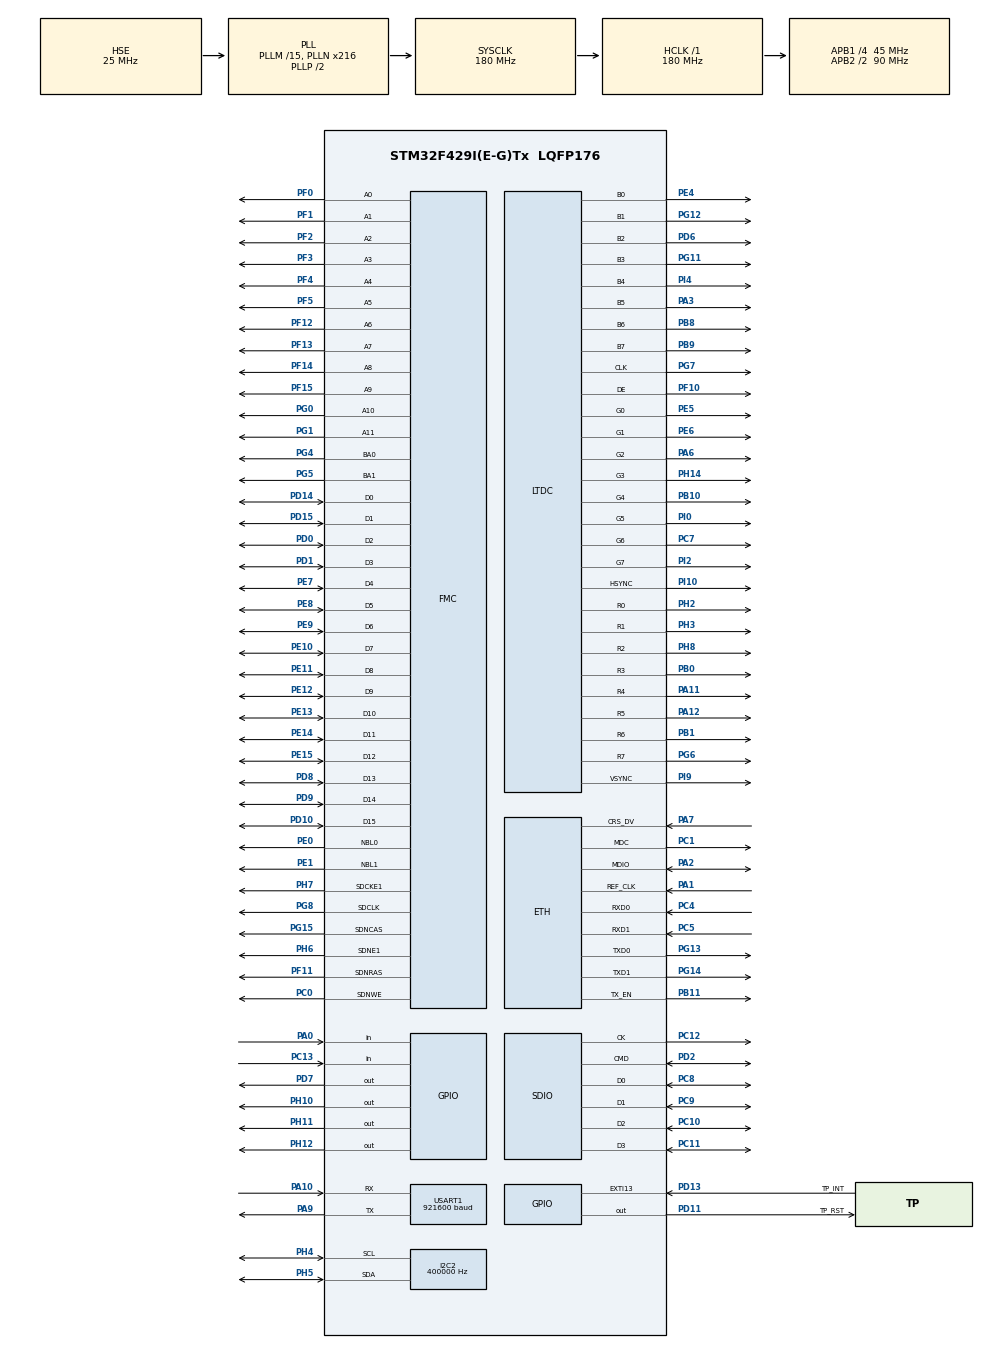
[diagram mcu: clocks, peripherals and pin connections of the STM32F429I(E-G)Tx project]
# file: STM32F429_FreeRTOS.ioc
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ADC1.Channel-0\#ChannelRegularConversion=ADC_CHANNEL_TEMPSENSOR
ADC1.NbrOfConversionFlag=1
ADC1.Rank-0\#ChannelRegularConversion=1
ADC1.SamplingTime-0\#ChannelRegularConversion=ADC_SAMPLETIME_3CYCLES
ADC1.master=1
DMA2D.ColorMode=DMA2D_OUTPUT_RGB888
DMA2D.Mode=DMA2D_M2M
Dma.Request0=SDIO_RX
Dma.Request1=SDIO_TX
Dma.SDIO_RX.0.Direction=DMA_PERIPH_TO_MEMORY
Dma.SDIO_RX.0.FIFOMode=DMA_FIFOMODE_ENABLE
Dma.SDIO_RX.0.FIFOThreshold=DMA_FIFO_THRESHOLD_FULL
Dma.SDIO_RX.0.Instance=DMA2_Stream3
Dma.SDIO_RX.0.MemBurst=DMA_MBURST_INC4
Dma.SDIO_RX.0.MemDataAlignment=DMA_MDATAALIGN_WORD
Dma.SDIO_RX.0.MemInc=DMA_MINC_ENABLE
Dma.SDIO_RX.0.Mode=DMA_PFCTRL
Dma.SDIO_RX.0.PeriphBurst=DMA_PBURST_INC4
Dma.SDIO_RX.0.PeriphDataAlignment=DMA_PDATAALIGN_WORD
Dma.SDIO_RX.0.PeriphInc=DMA_PINC_DISABLE
Dma.SDIO_RX.0.Priority=DMA_PRIORITY_LOW
Dma.SDIO_TX.1.Direction=DMA_MEMORY_TO_PERIPH
Dma.SDIO_TX.1.FIFOMode=DMA_FIFOMODE_ENABLE
Dma.SDIO_TX.1.FIFOThreshold=DMA_FIFO_THRESHOLD_FULL
Dma.SDIO_TX.1.Instance=DMA2_Stream6
Dma.SDIO_TX.1.MemBurst=DMA_MBURST_INC4
Dma.SDIO_TX.1.MemDataAlignment=DMA_MDATAALIGN_WORD
Dma.SDIO_TX.1.MemInc=DMA_MINC_ENABLE
Dma.SDIO_TX.1.Mode=DMA_PFCTRL
Dma.SDIO_TX.1.PeriphBurst=DMA_PBURST_INC4
Dma.SDIO_TX.1.PeriphDataAlignment=DMA_PDATAALIGN_WORD
Dma.SDIO_TX.1.PeriphInc=DMA_PINC_DISABLE
Dma.SDIO_TX.1.Priority=DMA_PRIORITY_LOW
ETH.MediaInterface=ETH_MEDIA_INTERFACE_RMII
ETH.PHY_DUPLEX_STATUS=0x0010
ETH.PHY_Name_RMII=userPHY
ETH.PHY_SPEED_STATUS=0x0004
ETH.PHY_SR=0x1F
ETH.PHY_User_Name=LAN8720A_PHY_ADDRESS
ETH.PhyAddress=0
FATFS._CODE_PAGE=936
FATFS._USE_LFN=2
FMC.CASLatency1=FMC_SDRAM_CAS_LATENCY_3
FMC.ExitSelfRefreshDelay1=7
FMC.LoadToActiveDelay1=2
FMC.RCDDelay1=2
FMC.RPDelay1=2
FMC.RPDelay2=2
FMC.ReadPipeDelay1=FMC_SDRAM_RPIPE_DELAY_1
FMC.ReadPipeDelay2=FMC_SDRAM_RPIPE_DELAY_1
FMC.RowCycleDelay1=7
FMC.RowCycleDelay2=7
FMC.SDClockPeriod1=FMC_SDRAM_CLOCK_PERIOD_2
FMC.SDClockPeriod2=FMC_SDRAM_CLOCK_PERIOD_2
FMC.SelfRefreshTime1=4
FMC.WriteRecoveryTime1=3
FREERTOS.Tasks01=defaultTask,24,128,StartDefaultTask,Default,(void *)semaphore,Dynamic,NULL,NULL
FREERTOS.configENABLE_FPU=1
FREERTOS.configGENERATE_RUN_TIME_STATS=1
FREERTOS.configLIBRARY_MAX_SYSCALL_INTERRUPT_PRIORITY=5
FREERTOS.configMINIMAL_STACK_SIZE=128
FREERTOS.configTOTAL_HEAP_SIZE=51200
FREERTOS.configUSE_STATS_FORMATTING_FUNCTIONS=1
I2C2.ClockSpeed=400000
I2C2.DutyCycle=I2C_DUTYCYCLE_2
I2C2.I2C_Mode=I2C_Fast
I2C2.OwnAddress=0x10
LTDC.ActiveH=600
LTDC.ActiveW=1024
LTDC.Alpha_L0=255
LTDC.BlendingFactor1_L0=LTDC_BLENDING_FACTOR1_CA
LTDC.BlendingFactor2_L0=LTDC_BLENDING_FACTOR2_CA
LTDC.FBStartAdress_L0=0xD0000000
LTDC.HBP=140
LTDC.HFP=160
LTDC.HSync=20
LTDC.ImageHeight_L0=600
LTDC.ImageWidth_L0=1024
LTDC.Layers=0
LTDC.PixelFormat_L0=LTDC_PIXEL_FORMAT_RGB888
LTDC.VBP=20
LTDC.VFP=12
LTDC.VSync=3
LTDC.WindowX1_L0=1024
LTDC.WindowY1_L0=600
LWIP.GATEWAY_ADDRESS=192.168.000.001
LWIP.IP_ADDRESS=192.168.000.123
LWIP.LWIP_DHCP=0
LWIP.LWIP_NETIF_STATUS_CALLBACK=1
LWIP.LWIP_SNTP=0
LWIP.LWIP_TCPIP_CORE_LOCKING=0
LWIP.LWIP_TCPIP_CORE_LOCKING_INPUT=0
LWIP.MEMP_NUM_SYS_TIMEOUT=7
LWIP.MEM_SIZE=(16*1024)
LWIP.NETMASK_ADDRESS=255.255.255.000
LWIP.TCPIP_THREAD_STACKSIZE=512 * 4
LWIP.Version=v2.1.2_Cube
Mcu.Family=STM32F4
Mcu.Name=STM32F429I(E-G)Tx
Mcu.Package=LQFP176
NVIC.DMA2_Stream3_IRQn=true\:7\:0\:true\:false\:true\:true\:false\:true
NVIC.DMA2_Stream6_IRQn=true\:7\:0\:true\:false\:true\:true\:false\:true
NVIC.ETH_IRQn=true\:5\:0\:false\:false\:true\:true\:false\:true
NVIC.EXTI15_10_IRQn=true\:5\:0\:false\:false\:true\:true\:true\:true
NVIC.PriorityGroup=NVIC_PRIORITYGROUP_4
NVIC.SDIO_IRQn=true\:6\:0\:true\:false\:true\:true\:true\:true
NVIC.TIM6_DAC_IRQn=true\:5\:0\:false\:false\:true\:true\:true\:true
NVIC.TIM7_IRQn=true\:15\:0\:false\:false\:true\:false\:false\:true
NVIC.TimeBase=TIM7_IRQn
NVIC.TimeBaseIP=TIM7
PA0/WKUP.Signal=GPIO_Input
PA1.Mode=RMII
PA1.Signal=ETH_REF_CLK
PA10.Mode=Asynchronous
PA10.Signal=USART1_RX
PA11.GPIO_Speed=GPIO_SPEED_FREQ_VERY_HIGH
PA11.Mode=RGB888
PA11.Signal=LTDC_R4
PA12.GPIO_Speed=GPIO_SPEED_FREQ_VERY_HIGH
PA12.Mode=RGB888
PA12.Signal=LTDC_R5
PA13.Mode=Serial_Wire
PA13.Signal=SYS_JTMS-SWDIO
PA14.Mode=Serial_Wire
PA14.Signal=SYS_JTCK-SWCLK
PA2.Mode=RMII
PA2.Signal=ETH_MDIO
PA3.GPIO_Speed=GPIO_SPEED_FREQ_VERY_HIGH
PA3.Mode=RGB888
PA3.Signal=LTDC_B5
PA6.GPIO_Speed=GPIO_SPEED_FREQ_VERY_HIGH
PA6.Mode=RGB888
PA6.Signal=LTDC_G2
PA7.Mode=RMII
PA7.Signal=ETH_CRS_DV
PA9.Mode=Asynchronous
PA9.Signal=USART1_TX
PB0.GPIO_Speed=GPIO_SPEED_FREQ_VERY_HIGH
PB0.Mode=RGB888
PB0.Signal=LTDC_R3
PB1.GPIO_Speed=GPIO_SPEED_FREQ_VERY_HIGH
PB1.Mode=RGB888
PB1.Signal=LTDC_R6
PB10.GPIO_Speed=GPIO_SPEED_FREQ_VERY_HIGH
PB10.Mode=RGB888
PB10.Signal=LTDC_G4
PB11.Mode=RMII
PB11.Signal=ETH_TX_EN
PB8.GPIO_Speed=GPIO_SPEED_FREQ_VERY_HIGH
PB8.Mode=RGB888
PB8.Signal=LTDC_B6
PB9.GPIO_Speed=GPIO_SPEED_FREQ_VERY_HIGH
PB9.Mode=RGB888
PB9.Signal=LTDC_B7
PC0.Signal=FMC_SDNWE
PC1.Mode=RMII
PC1.Signal=ETH_MDC
PC10.GPIO_PuPd=GPIO_NOPULL
PC10.Mode=SD_4_bits_Wide_bus
PC10.Signal=SDIO_D2
PC11.GPIO_PuPd=GPIO_NOPULL
PC11.Mode=SD_4_bits_Wide_bus
PC11.Signal=SDIO_D3
PC12.GPIO_PuPd=GPIO_NOPULL
PC12.Mode=SD_4_bits_Wide_bus
PC12.Signal=SDIO_CK
PC13.Signal=GPIO_Input
PC14/OSC32_IN.Mode=LSE-External-Oscillator
PC14/OSC32_IN.Signal=RCC_OSC32_IN
PC15/OSC32_OUT.Mode=LSE-External-Oscillator
PC15/OSC32_OUT.Signal=RCC_OSC32_OUT
PC4.Mode=RMII
PC4.Signal=ETH_RXD0
PC5.Mode=RMII
PC5.Signal=ETH_RXD1
PC7.GPIO_Speed=GPIO_SPEED_FREQ_VERY_HIGH
PC7.Mode=RGB888
PC7.Signal=LTDC_G6
PC8.GPIO_PuPd=GPIO_NOPULL
PC8.Mode=SD_4_bits_Wide_bus
PC8.Signal=SDIO_D0
PC9.GPIO_PuPd=GPIO_NOPULL
PC9.Mode=SD_4_bits_Wide_bus
PC9.Signal=SDIO_D1
PD0.Signal=FMC_D2_DA2
PD1.Signal=FMC_D3_DA3
PD10.Signal=FMC_D15_DA15
PD11.GPIO_Label=TP_RST
PD11.Signal=GPIO_Output
PD13.GPIO_Label=TP_INT
PD13.GPIO_ModeDefaultEXTI=GPIO_MODE_IT_RISING
PD13.Signal=GPXTI13
PD14.Signal=FMC_D0_DA0
PD15.Signal=FMC_D1_DA1
PD2.GPIO_PuPd=GPIO_NOPULL
PD2.Mode=SD_4_bits_Wide_bus
PD2.Signal=SDIO_CMD
PD6.GPIO_Speed=GPIO_SPEED_FREQ_VERY_HIGH
PD6.Mode=RGB888
PD6.Signal=LTDC_B2
PD7.PinState=GPIO_PIN_SET
PD7.Signal=GPIO_Output
PD8.Signal=FMC_D13_DA13
PD9.Signal=FMC_D14_DA14
PE0.Signal=FMC_NBL0
PE1.Signal=FMC_NBL1
PE10.Signal=FMC_D7_DA7
PE11.Signal=FMC_D8_DA8
PE12.Signal=FMC_D9_DA9
PE13.Signal=FMC_D10_DA10
PE14.Signal=FMC_D11_DA11
PE15.Signal=FMC_D12_DA12
PE4.GPIO_Speed=GPIO_SPEED_FREQ_VERY_HIGH
PE4.Mode=RGB888
PE4.Signal=LTDC_B0
PE5.GPIO_Speed=GPIO_SPEED_FREQ_VERY_HIGH
PE5.Mode=RGB888
PE5.Signal=LTDC_G0
PE6.GPIO_Speed=GPIO_SPEED_FREQ_VERY_HIGH
PE6.Mode=RGB888
PE6.Signal=LTDC_G1
PE7.Signal=FMC_D4_DA4
PE8.Signal=FMC_D5_DA5
PE9.Signal=FMC_D6_DA6
PF0.Signal=FMC_A0
PF1.Signal=FMC_A1
PF10.GPIO_Speed=GPIO_SPEED_FREQ_VERY_HIGH
PF10.Mode=RGB888
PF10.Signal=LTDC_DE
PF11.Signal=FMC_SDNRAS
PF12.Signal=FMC_A6
PF13.Signal=FMC_A7
PF14.Signal=FMC_A8
PF15.Signal=FMC_A9
PF2.Signal=FMC_A2
PF3.Signal=FMC_A3
PF4.Signal=FMC_A4
PF5.Signal=FMC_A5
PG0.Signal=FMC_A10
PG1.Signal=FMC_A11
PG11.GPIO_Speed=GPIO_SPEED_FREQ_VERY_HIGH
PG11.Mode=RGB888
PG11.Signal=LTDC_B3
PG12.GPIO_Speed=GPIO_SPEED_FREQ_VERY_HIGH
PG12.Mode=RGB888
PG12.Signal=LTDC_B1
PG13.Mode=RMII
PG13.Signal=ETH_TXD0
PG14.Mode=RMII
PG14.Signal=ETH_TXD1
PG15.Signal=FMC_SDNCAS
PG4.Signal=FMC_A14_BA0
PG5.Signal=FMC_A15_BA1
PG6.GPIO_Speed=GPIO_SPEED_FREQ_VERY_HIGH
PG6.Mode=RGB888
PG6.Signal=LTDC_R7
PG7.GPIO_Speed=GPIO_SPEED_FREQ_VERY_HIGH
PG7.Mode=RGB888
PG7.Signal=LTDC_CLK
PG8.Signal=FMC_SDCLK
PH0/OSC_IN.Mode=HSE-External-Oscillator
PH0/OSC_IN.Signal=RCC_OSC_IN
PH1/OSC_OUT.Mode=HSE-External-Oscillator
PH1/OSC_OUT.Signal=RCC_OSC_OUT
PH10.PinState=GPIO_PIN_SET
PH10.Signal=GPIO_Output
PH11.PinState=GPIO_PIN_SET
PH11.Signal=GPIO_Output
PH12.PinState=GPIO_PIN_SET
PH12.Signal=GPIO_Output
PH14.GPIO_Speed=GPIO_SPEED_FREQ_VERY_HIGH
PH14.Mode=RGB888
PH14.Signal=LTDC_G3
PH2.GPIO_Speed=GPIO_SPEED_FREQ_VERY_HIGH
PH2.Mode=RGB888
PH2.Signal=LTDC_R0
PH3.GPIO_Speed=GPIO_SPEED_FREQ_VERY_HIGH
PH3.Mode=RGB888
PH3.Signal=LTDC_R1
PH4.Mode=I2C
PH4.Signal=I2C2_SCL
PH5.Mode=I2C
PH5.Signal=I2C2_SDA
PH6.Mode=SdramChipSelect2_1
PH6.Signal=FMC_SDNE1
PH7.Mode=SdramChipSelect2_1
PH7.Signal=FMC_SDCKE1
PH8.GPIO_Speed=GPIO_SPEED_FREQ_VERY_HIGH
PH8.Mode=RGB888
PH8.Signal=LTDC_R2
PI0.GPIO_Speed=GPIO_SPEED_FREQ_VERY_HIGH
PI0.Mode=RGB888
PI0.Signal=LTDC_G5
PI10.GPIO_Speed=GPIO_SPEED_FREQ_VERY_HIGH
PI10.Mode=RGB888
PI10.Signal=LTDC_HSYNC
PI2.GPIO_Speed=GPIO_SPEED_FREQ_VERY_HIGH
PI2.Mode=RGB888
PI2.Signal=LTDC_G7
PI4.GPIO_Speed=GPIO_SPEED_FREQ_VERY_HIGH
PI4.Mode=RGB888
PI4.Signal=LTDC_B4
PI9.GPIO_Speed=GPIO_SPEED_FREQ_VERY_HIGH
PI9.Mode=RGB888
PI9.Signal=LTDC_VSYNC
ProjectManager.HeapSize=0x1000
ProjectManager.StackSize=0x1000
ProjectManager.TargetToolchain=STM32CubeIDE
RCC.48MHZClocksFreq_Value=45000000
RCC.AHBFreq_Value=180000000
RCC.APB1CLKDivider=RCC_HCLK_DIV4
RCC.APB1Freq_Value=45000000
RCC.APB1TimFreq_Value=90000000
RCC.APB2CLKDivider=RCC_HCLK_DIV2
RCC.APB2Freq_Value=90000000
RCC.APB2TimFreq_Value=180000000
RCC.CortexFreq_Value=180000000
RCC.HCLKFreq_Value=180000000
RCC.HSE_VALUE=25000000
RCC.HSI_VALUE=16000000
RCC.PLLM=15
RCC.PLLN=216
RCC.PLLQ=8
RCC.PLLSAIN=60
RCC.PLLSourceVirtual=RCC_PLLSOURCE_HSE
RCC.SYSCLKFreq_VALUE=180000000
RCC.SYSCLKSource=RCC_SYSCLKSOURCE_PLLCLK
RCC.VCOOutputFreq_Value=360000000
SDIO.ClockDiv=0
SDIO.HardwareFlowControl=SDIO_HARDWARE_FLOW_CONTROL_DISABLE
SH.FMC_A0.0=FMC_A0,12b-sda1
SH.FMC_A1.0=FMC_A1,12b-sda1
SH.FMC_A10.0=FMC_A10,12b-sda1
SH.FMC_A11.0=FMC_A11,12b-sda1
SH.FMC_A14_BA0.0=FMC_BA0,FourSdramBanks1
SH.FMC_A15_BA1.0=FMC_BA1,FourSdramBanks1
SH.FMC_A2.0=FMC_A2,12b-sda1
SH.FMC_A3.0=FMC_A3,12b-sda1
SH.FMC_A4.0=FMC_A4,12b-sda1
SH.FMC_A5.0=FMC_A5,12b-sda1
SH.FMC_A6.0=FMC_A6,12b-sda1
SH.FMC_A7.0=FMC_A7,12b-sda1
SH.FMC_A8.0=FMC_A8,12b-sda1
SH.FMC_A9.0=FMC_A9,12b-sda1
SH.FMC_D0_DA0.0=FMC_D0,sd-16b-d1
SH.FMC_D10_DA10.0=FMC_D10,sd-16b-d1
SH.FMC_D11_DA11.0=FMC_D11,sd-16b-d1
SH.FMC_D12_DA12.0=FMC_D12,sd-16b-d1
SH.FMC_D13_DA13.0=FMC_D13,sd-16b-d1
SH.FMC_D14_DA14.0=FMC_D14,sd-16b-d1
SH.FMC_D15_DA15.0=FMC_D15,sd-16b-d1
SH.FMC_D1_DA1.0=FMC_D1,sd-16b-d1
SH.FMC_D2_DA2.0=FMC_D2,sd-16b-d1
SH.FMC_D3_DA3.0=FMC_D3,sd-16b-d1
SH.FMC_D4_DA4.0=FMC_D4,sd-16b-d1
SH.FMC_D5_DA5.0=FMC_D5,sd-16b-d1
SH.FMC_D6_DA6.0=FMC_D6,sd-16b-d1
SH.FMC_D7_DA7.0=FMC_D7,sd-16b-d1
SH.FMC_D8_DA8.0=FMC_D8,sd-16b-d1
SH.FMC_D9_DA9.0=FMC_D9,sd-16b-d1
SH.FMC_NBL0.0=FMC_NBL0,Sd2ByteEnable1
SH.FMC_NBL1.0=FMC_NBL1,Sd2ByteEnable1
SH.FMC_SDCLK.0=FMC_SDCLK,12b-sda1
SH.FMC_SDNCAS.0=FMC_SDNCAS,12b-sda1
SH.FMC_SDNRAS.0=FMC_SDNRAS,12b-sda1
SH.FMC_SDNWE.0=FMC_SDNWE,12b-sda1
TIM6.AutoReloadPreload=TIM_AUTORELOAD_PRELOAD_ENABLE
TIM6.Period=899
TIM6.Prescaler=9
TIM6.TIM_MasterOutputTrigger=TIM_TRGO_UPDATE
USART1.BaudRate=921600
USART1.VirtualMode=VM_ASYNC
VP_ADC1_TempSens_Input.Mode=IN-TempSens
VP_CRC_VS_CRC.Mode=CRC_Activate
VP_DMA2D_VS_DMA2D.Mode=DMA2D_Activate
VP_FATFS_VS_SDIO.Mode=SDIO
VP_FREERTOS_VS_CMSIS_V2.Mode=CMSIS_V2
VP_LWIP_VS_Enabled.Mode=Enabled
VP_RNG_VS_RNG.Mode=RNG_Activate
VP_SYS_VS_tim7.Mode=TIM7
VP_TIM6_VS_ClockSourceINT.Mode=Enable_Timer
board=custom

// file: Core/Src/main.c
/* USER CODE BEGIN Header */
/**
  ******************************************************************************
  * @file           : main.c
  * @brief          : Main program body
  ******************************************************************************
  * @attention
  *
  * Copyright (c) 2023 STMicroelectronics.
  * All rights reserved.
  *
  * This software is licensed under terms that can be found in the LICENSE file
  * in the root directory of this software component.
  * If no LICENSE file comes with this software, it is provided AS-IS.
  *
  ******************************************************************************
  */
#include <stdio.h>
#include "sdio.h"
/* USER CODE END Header */
#include "main.h"
#include "cmsis_os.h"
#include "adc.h"
#include "crc.h"
#include "dma.h"
#include "dma2d.h"
#include "fatfs.h"
#include "i2c.h"
#include "ltdc.h"
#include "lwip.h"
#include "rng.h"
#include "sdio.h"
#include "tim.h"
#include "usart.h"
#include "gpio.h"
#include "fmc.h"

void SystemClock_Config(void);
void MX_FREERTOS_Init(void);

int main(void)
{

  /* MCU Configuration--------------------------------------------------------*/

  /* Reset of all peripherals, Initializes the Flash interface and the Systick. */
  HAL_Init();

  /* Configure the system clock */
  SystemClock_Config();

  /* Initialize all configured peripherals */
  MX_GPIO_Init();
  MX_SDIO_SD_Init();
  MX_USART1_UART_Init();
  MX_DMA_Init();
  MX_FATFS_Init();
  MX_CRC_Init();
  MX_DMA2D_Init();
  MX_FMC_Init();
  MX_LTDC_Init();
  MX_RNG_Init();
  MX_ADC1_Init();
  MX_TIM6_Init();
  MX_I2C2_Init();

  /* Init scheduler */
  osKernelInitialize();  /* Call init function for freertos objects (in freertos.c) */
  MX_FREERTOS_Init();
  /* Start scheduler */
  osKernelStart();

  /* We should never get here as control is now taken by the scheduler */
  /* Infinite loop */
  while (1)
  {

  }
}

void SystemClock_Config(void)
{
  RCC_OscInitTypeDef RCC_OscInitStruct = {0};
  RCC_ClkInitTypeDef RCC_ClkInitStruct = {0};

  /** Configure the main internal regulator output voltage
  */
  __HAL_RCC_PWR_CLK_ENABLE();
  __HAL_PWR_VOLTAGESCALING_CONFIG(PWR_REGULATOR_VOLTAGE_SCALE1);
  /** Initializes the RCC Oscillators according to the specified parameters
  * in the RCC_OscInitTypeDef structure.
  */
  RCC_OscInitStruct.OscillatorType = RCC_OSCILLATORTYPE_HSE;
  RCC_OscInitStruct.HSEState = RCC_HSE_ON;
  RCC_OscInitStruct.PLL.PLLState = RCC_PLL_ON;
  RCC_OscInitStruct.PLL.PLLSource = RCC_PLLSOURCE_HSE;
  RCC_OscInitStruct.PLL.PLLM = 15;
  RCC_OscInitStruct.PLL.PLLN = 216;
  RCC_OscInitStruct.PLL.PLLP = RCC_PLLP_DIV2;
  RCC_OscInitStruct.PLL.PLLQ = 8;
  if (HAL_RCC_OscConfig(&RCC_OscInitStruct) != HAL_OK)
  {
    Error_Handler();
  }
  /** Activate the Over-Drive mode
  */
  if (HAL_PWREx_EnableOverDrive() != HAL_OK)
  {
    Error_Handler();
  }
  /** Initializes the CPU, AHB and APB buses clocks
  */
  RCC_ClkInitStruct.ClockType = RCC_CLOCKTYPE_HCLK|RCC_CLOCKTYPE_SYSCLK
                              |RCC_CLOCKTYPE_PCLK1|RCC_CLOCKTYPE_PCLK2;
  RCC_ClkInitStruct.SYSCLKSource = RCC_SYSCLKSOURCE_PLLCLK;
  RCC_ClkInitStruct.AHBCLKDivider = RCC_SYSCLK_DIV1;
  RCC_ClkInitStruct.APB1CLKDivider = RCC_HCLK_DIV4;
  RCC_ClkInitStruct.APB2CLKDivider = RCC_HCLK_DIV2;

  if (HAL_RCC_ClockConfig(&RCC_ClkInitStruct, FLASH_LATENCY_5) != HAL_OK)
  {
    Error_Handler();
  }
}

void HAL_TIM_PeriodElapsedCallback(TIM_HandleTypeDef *htim)
{
  if (htim->Instance == TIM7) {
    HAL_IncTick();
  }
  /* USER CODE BEGIN Callback 1 */
  if(htim->Instance == TIM6){
  		timer_cnt++;
  	}
  /* USER CODE END Callback 1 */
}

void Error_Handler(void)
{
  __disable_irq();
  while (1)
  {
  }
}

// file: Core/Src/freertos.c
/* USER CODE BEGIN Header */
/**
  ******************************************************************************
  * File Name          : freertos.c
  * Description        : Code for freertos applications
  ******************************************************************************
  * @attention
  *
  * Copyright (c) 2023 STMicroelectronics.
  * All rights reserved.
  *
  * This software is licensed under terms that can be found in the LICENSE file
  * in the root directory of this software component.
  * If no LICENSE file comes with this software, it is provided AS-IS.
  *
  ******************************************************************************
  */
/* USER CODE END Header */

#include "FreeRTOS.h"
#include "task.h"
#include "main.h"
#include "cmsis_os.h"

/* USER CODE BEGIN Includes */
#include "fatfs.h"
#include "sdio.h"
#include <string.h>
#include "dma2d.h"
#include <stdio.h>
#include "_1.h"
#include "adc.h"
#include "tim.h"
#include "i2c.h"
#include "mqtt.h"
#include "GSL1680.h"
/* USER CODE END Includes */

/* USER CODE BEGIN PD */
#define IMGRAM_BASE_ADDR 0xD0000000

/* USER CODE END PD */

/* USER CODE BEGIN Variables */

/************Fatfs Task****************/
osThreadId_t FatfsTaskHandle;
const osThreadAttr_t FatfsTask_attributes = {
  .name = "fatfsTask",
  .stack_size = 1024 * 4,
  .priority = (osPriority_t) osPriorityNormal,
};

/************LCD Task****************/
osThreadId_t LcdTaskHandle;
const osThreadAttr_t LcdTask_attributes = {
  .name = "lcdTask",
  .stack_size = 128 * 4,
  .priority = (osPriority_t) osPriorityNormal,
};

/************Touch Task****************/
osThreadId_t TouchTaskHandle;
const osThreadAttr_t TouchTask_attributes = {
  .name = "TouchTask",
  .stack_size = 512 * 4,
  .priority = (osPriority_t) osPriorityNormal,
};

/************Info Task****************/
osThreadId_t InfoTaskHandle;
const osThreadAttr_t InfoTask_attributes = {
  .name = "InfoTask",
  .stack_size = 512 * 4,
  .priority = (osPriority_t) osPriorityNormal,
};

/************MQTT Task****************/
osThreadId_t MQTT_TaskHandle;
const osThreadAttr_t MQTT_Task_attributes = {
  .name = "MQTT_Task",
  .stack_size = 612 * 4,
  .priority = (osPriority_t) osPriorityNormal,
};

/* USER CODE END Variables */
/* Definitions for defaultTask */
osThreadId_t defaultTaskHandle;
const osThreadAttr_t defaultTask_attributes = {
  .name = "defaultTask",
  .stack_size = 128 * 4,
  .priority = (osPriority_t) osPriorityNormal,
};

/* USER CODE BEGIN FunctionPrototypes */
void FatfsTask(void *argument);
void LcdTask(void *argument);
void InfoTask(void *argument);
void TouchTask(void *argument);
void MQTT_Task(void *argument);
//static void draw_xy_wh_c(uint16_t x, uint16_t y, uint16_t w, uint16_t h, uint32_t c);

/* USER CODE END FunctionPrototypes */

void StartDefaultTask(void *argument);

extern void MX_LWIP_Init(void);
void MX_FREERTOS_Init(void); /* (MISRA C 2004 rule 8.1) */

/* Hook prototypes */
void configureTimerForRunTimeStats(void);
unsigned long getRunTimeCounterValue(void);

/* USER CODE BEGIN 1 */
/* Functions needed when configGENERATE_RUN_TIME_STATS is on */
__weak void configureTimerForRunTimeStats(void)
{

}

__weak unsigned long getRunTimeCounterValue(void)
{
	return get_time_val();
}
/* USER CODE END 1 */

void MX_FREERTOS_Init(void) {

  /* USER CODE BEGIN RTOS_SEMAPHORES */
  /* add semaphores, ... */
	osSemaphoreId_t semaphore;
	semaphore = osSemaphoreNew (1, 0, NULL);

  /* USER CODE END RTOS_SEMAPHORES */

  /* Create the thread(s) */
  /* creation of defaultTask */
  defaultTaskHandle = osThreadNew(StartDefaultTask, (void *)semaphore, &defaultTask_attributes);

  /* USER CODE BEGIN RTOS_THREADS */
  /* add threads, ... */
  FatfsTaskHandle = osThreadNew(FatfsTask, NULL, &FatfsTask_attributes);
	LcdTaskHandle = osThreadNew(LcdTask, NULL, &LcdTask_attributes);
	TouchTaskHandle = osThreadNew(TouchTask, NULL, &TouchTask_attributes);
	InfoTaskHandle = osThreadNew(InfoTask, NULL, &InfoTask_attributes);
	MQTT_TaskHandle = osThreadNew(MQTT_Task, (void *)semaphore, &MQTT_Task_attributes);
  /* USER CODE END RTOS_THREADS */

}

void StartDefaultTask(void *argument)
{
  /* init code for LWIP */
  MX_LWIP_Init();
  /* USER CODE BEGIN StartDefaultTask */
  osSemaphoreId_t semaphore = (osSemaphoreId_t)argument;
  osSemaphoreRelease (semaphore);

    for(;;)
    {
    	HAL_GPIO_TogglePin(GPIOH, GPIO_PIN_10);
      osDelay(500);
    }
  /* USER CODE END StartDefaultTask */
}

/* USER CODE BEGIN Application */

static void draw_xy_wh_c(uint16_t x, uint16_t y, uint16_t w, uint16_t h, uint32_t c){
	dma2d_put_src_wh_c(IMGRAM_BASE_ADDR + y * 1024 * 3 + x * 3, w, h, c);
}

static void draw_xy_wh_img(uint16_t x, uint16_t y, uint16_t w, uint16_t h, const uint8_t* src){
//	dma2d_put_mem_mem(src, IMGRAM_BASE_ADDR + y * 1024 * 3 + x * 3, w, h);
	uint8_t *p = (uint8_t*)(IMGRAM_BASE_ADDR + y * 1024 * 3 + x * 3);
	uint32_t index = 0;
	int i = 0, j = 0;
	for(i = 0 ; i < h; i++){
		for(j = 0 ; j < w; j++){
				*p = src[index++];
				p++;
				*p = src[index++];
				p++;
				*p = src[index++];
				p++;
		}

		p=p+(1024-w)*3;
	}
}

void FatfsTask(void *argument){
	int ret = 0;
	char path[50];
	//const char *write_buff = "hello world! xsdhjkshfksehifuhseuhfuisdhfuise";
	char readbuff[100];
	HAL_SD_CardInfoTypeDef pCardInfo;
	FIL SDFile1, SDFile2;
	UINT bw = 0, br = 0;
	/*1、挂载文件系统*/
	BYTE work[_MAX_SS];
	ret = f_mount (&SDFatFS, (const TCHAR*)SDPath, 1);
	if(ret == FR_NO_FILESYSTEM){
		ret = f_mkfs ((const TCHAR*)SDPath, FM_FAT32, 0, work, sizeof(work));
		if(ret != FR_OK){
				printf("f_mkfs is err:%d\r\n",ret);
				goto loop;
		}
		f_mount (&SDFatFS, SDPath, 1);
	}else if (ret != FR_OK){
			printf("f_mount is err:%d\r\n",ret);
			goto loop;
	}else{
		printf("f_mount is ok\r\n");
	}
	ret = HAL_SD_GetCardInfo(&hsd, &pCardInfo);
	if(ret != HAL_OK){
		printf("HAL_SD_GetCardInfo is err\r\n");
	}else{
		printf("Initialize SD card successfully!\r\n");
		 // 打印SD卡基本信息
		 printf(" SD card information! \r\n");
		 printf(" CardBlockSize : %ld \r\n", pCardInfo.BlockSize);   // 块大小
		 printf(" CardBlockNbr : %ld \r\n", pCardInfo.BlockNbr);   // 块数量
		 printf(" CardCapacity  : %.2f MB \r\n",(double)((unsigned long long)pCardInfo.BlockSize * pCardInfo.BlockNbr/1024)/1024);// 显示容量 // @suppress("Float formatting support")
		 printf(" LogBlockNbr   : %ld \r\n", pCardInfo.LogBlockNbr); // 逻辑块数量
		 printf(" LogBlockSize  : %ld \r\n", pCardInfo.LogBlockSize);// 逻辑块大小
		 printf(" RCA           : %ld \r\n", pCardInfo.RelCardAdd);  // 卡相对地址
		 printf(" CardType      : %ld \r\n", pCardInfo.CardType);    // 卡类型
		 // 读取并打印SD卡的CID信息
		 HAL_SD_CardCIDTypeDef sdcard_cid;
		 HAL_SD_GetCardCID(&hsd,&sdcard_cid);
		 printf(" ManufacturerID: %d \r\n",sdcard_cid.ManufacturerID);
	}
		/*2、新建test.txt文件*/
		sprintf(path, "%stest.txt",SDPath);
		ret = f_open (&SDFile1, path, FA_READ | FA_WRITE);
		if(ret != FR_OK){
			printf("f_open is err:%d\r\n",ret);
			goto f_open_err;
		}
		/*将缓存写入文件

		ret = f_write (&SDFile1, write_buff, strlen(write_buff), &bw);
		if(ret != FR_OK){
				printf("f_write is err:%d\r\n",ret);
				goto f_write_err;
		}
		printf("write is ok: bw:%d\r\n",bw);*/
		/*读取文件 0:/xixi.txt*/
		sprintf(path, "%sxixi.txt",SDPath);
		ret = f_open (&SDFile2, path, FA_READ);
		if(ret != FR_OK){
			printf("f_open is err:%d\r\n",ret);
		}
		ret = f_read (&SDFile2, readbuff, 16, &br);
		if(ret != FR_OK){
				printf("f_read is err:%d\r\n",ret);
		}
		readbuff[16] = 0;
		printf("%s\r\n",readbuff);
		f_close (&SDFile1);
		f_close (&SDFile2);
		f_mount(NULL, SDPath, 1);
		goto loop;
		/* Infinite loop */
//	f_write_err:
//		f_close (&SDFile1);
	f_open_err:
		f_mount(NULL, SDPath, 1);
		loop:
	while(1){
		osDelay(1000);
	};
}

void LcdTask(void *argument){

	while(1){
		draw_xy_wh_c(0, 0, 1024, 600, 0);
		draw_xy_wh_c(255, 149, 512, 300, 0xFF0000);
		osDelay(5000);
		draw_xy_wh_c(255, 149, 512, 300, 0x00FF00);
		osDelay(5000);
		draw_xy_wh_c(255, 149, 512, 300, 0x0000FF);
		osDelay(5000);
		draw_xy_wh_c(255, 149, 512, 300, 0xFFFFFF);
		osDelay(5000);
		draw_xy_wh_c(0, 0, 1024, 600, 0);
		draw_xy_wh_img(411, 199, 200, 200, _1_IMAGE);
		osDelay(5000);
	}
}

void InfoTask(void *argument){
	float temp = 0.;
	char buff[500];
	osDelay(1000);
	while(1){
		temp = get_cpu_temp();
		printf("\r\n*******************Sys Info*******************\r\n");
		printf("CPU Temp: %.2f'C\r\n", temp); // @suppress("Float formatting support")
		vTaskList(buff);
		printf("TaskName\tSta\tPrior\tFStack\tID\r\n");
		printf("%s\r\n", buff);
		vTaskGetRunTimeStats(buff);
		printf("TaskName\tRunTime\t\tCPUload\r\n");
		printf("%s\r\n", buff);
		printf("*******************End Info*******************\r\n");
		osDelay(5000);
	}
}

static void mqtt_request_cb_fun(void *arg, err_t err){
	if(err == ERR_OK){
		printf("topic%d request is ok\r\n", (int)arg);
	}else printf("error :%d\r\n", err);
}

static void mqtt_incoming_publish_cb(void *arg, const char *topic, u32_t tot_len){
	printf("topic: %s, tot_len: %ld\r\n", topic, tot_len);
}

static void mqtt_incoming_data_cb(void *arg, const u8_t *data, u16_t len, u8_t flags){
	printf("data: %s, tot_len: %d, flags: %d\r\n",data, len, flags);
}

void MQTT_Task(void *argument){
	err_t ret = 0;
	osSemaphoreId_t semaphore = (osSemaphoreId_t)argument;
	osSemaphoreAcquire (semaphore, 0xFFFFFFFF);
	mqtt_client_t *client;
	ip_addr_t ipaddr;
	IP4_ADDR(&ipaddr, 192, 168, 0, 110);
	const struct mqtt_connect_client_info_t client_info = {
		.client_id = "12",
		.client_pass = NULL,
		.client_user = "lzh",
		.keep_alive = 60,
	};
	client = mqtt_client_new();
	ret = mqtt_client_connect(client, &ipaddr, 1883, NULL, NULL, &client_info);
	if(ret != ERR_OK){
		printf("mqtt_client_connect is error \r\n");
		vTaskDelete(NULL);
	}
	printf("mqtt_client_connect is ok \r\n");
	mqtt_set_inpub_callback(client, mqtt_incoming_publish_cb, mqtt_incoming_data_cb, NULL);
	mqtt_subscribe(client, "topic1", 0, mqtt_request_cb_fun, (void*)1);
	mqtt_subscribe(client, "topic2", 0, mqtt_request_cb_fun, (void*)2);
	mqtt_subscribe(client, "topic3", 0, mqtt_request_cb_fun, (void*)3);
	const char * payload = "msg from stm32";

	while(1){
		ret = mqtt_publish(client, "topic4", payload, strlen(payload), 2, 0, NULL, NULL);
		if(ret == 0){
			printf("mqtt_publish: %s\r\n", payload);
		}else{
			printf("mqtt_publish error:%d\r\n", ret);
		}
		osDelay(5000);
	}
}

static inline uint16_t join_bytes(uint8_t a, uint8_t b)
{
	uint16_t ab = 0;
	ab = ab | a;
	ab = ab << 8 | b;
	return ab;
}

void TouchTask(void *argument){
	taskENTER_CRITICAL();
	GSL_Init();
	taskEXIT_CRITICAL();
	uint8_t data[24];
	HAL_StatusTypeDef err;
	while(1){
		if(osSemaphoreAcquire(Touchsemaphore, osWaitForever) == osOK){
				err = GSL_Receive(GSL_REG_DATA, data, 24, 0xFFFF);
				if(err != HAL_OK){
					printf("GSL_Receive data is error: %d\r\n", err);
				}else{
					printf("%d:(%d, %d)\r\n", data[0], join_bytes(data[6 + 4 * 0 + 1] & 0xf, data[6 + 4 * 0]), join_bytes(data[4 + 4 * 0 + 1], data[4 + 4 * 0]));
				}
		}
	}
}

/* USER CODE END Application */
